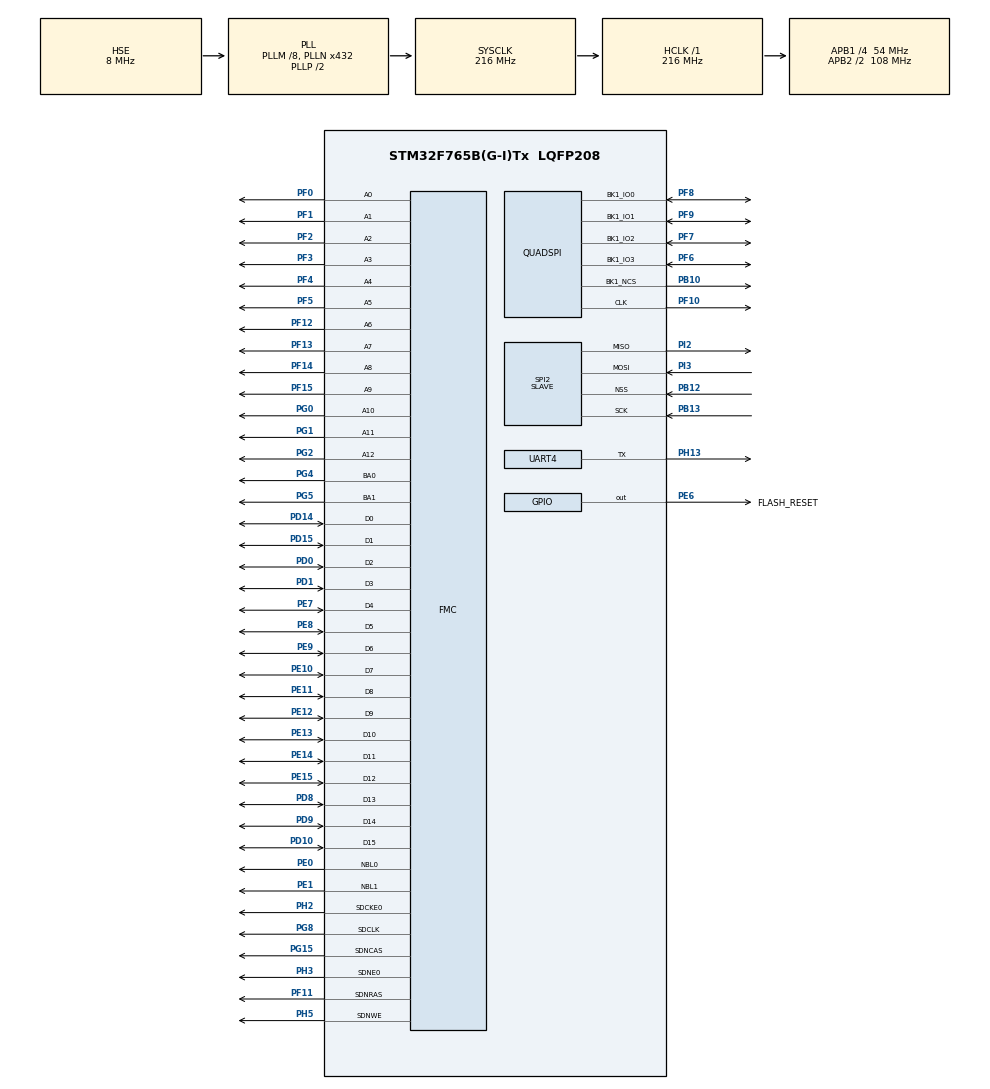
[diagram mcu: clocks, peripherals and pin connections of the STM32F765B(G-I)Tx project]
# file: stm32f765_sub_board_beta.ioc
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CORTEX_M7.ART_ACCLERATOR_ENABLE=1
CORTEX_M7.CPU_DCache=Enabled
CORTEX_M7.CPU_ICache=Enabled
CORTEX_M7.PREFETCH_ENABLE=1
FMC.CASLatency1=FMC_SDRAM_CAS_LATENCY_3
FMC.ColumnBitsNumber1=FMC_SDRAM_COLUMN_BITS_NUM_9
FMC.ExitSelfRefreshDelay1=8
FMC.LoadToActiveDelay1=2
FMC.RCDDelay1=2
FMC.RPDelay1=2
FMC.RPDelay2=2
FMC.ReadBurst1=FMC_SDRAM_RBURST_ENABLE
FMC.ReadBurst2=FMC_SDRAM_RBURST_ENABLE
FMC.ReadPipeDelay1=FMC_SDRAM_RPIPE_DELAY_1
FMC.ReadPipeDelay2=FMC_SDRAM_RPIPE_DELAY_1
FMC.RowCycleDelay1=6
FMC.RowCycleDelay2=6
FMC.SDClockPeriod1=FMC_SDRAM_CLOCK_PERIOD_2
FMC.SDClockPeriod2=FMC_SDRAM_CLOCK_PERIOD_2
FMC.SelfRefreshTime1=6
FMC.WriteProtection1=FMC_SDRAM_WRITE_PROTECTION_DISABLE
FMC.WriteRecoveryTime1=4
Mcu.Family=STM32F7
Mcu.Name=STM32F765B(G-I)Tx
Mcu.Package=LQFP208
NVIC.PriorityGroup=NVIC_PRIORITYGROUP_4
NVIC.SPI2_IRQn=true\:2\:0\:true\:true\:true\:1
NVIC.TIM8_TRG_COM_TIM14_IRQn=true\:14\:0\:true\:false\:true
NVIC.UART4_IRQn=true\:6\:0\:true\:true\:true\:2
PB10.Mode=Single Bank 1
PB10.Signal=QUADSPI_BK1_NCS
PB12.Mode=NSS_Signal_Hard_Input
PB12.Signal=SPI2_NSS
PB13.Mode=Full_Duplex_Slave
PB13.Signal=SPI2_SCK
PD0.Signal=FMC_D2_DA2
PD1.Signal=FMC_D3_DA3
PD10.Signal=FMC_D15_DA15
PD14.Signal=FMC_D0_DA0
PD15.Signal=FMC_D1_DA1
PD8.Signal=FMC_D13_DA13
PD9.Signal=FMC_D14_DA14
PE0.Signal=FMC_NBL0
PE1.Signal=FMC_NBL1
PE10.Signal=FMC_D7_DA7
PE11.Signal=FMC_D8_DA8
PE12.Signal=FMC_D9_DA9
PE13.Signal=FMC_D10_DA10
PE14.Signal=FMC_D11_DA11
PE15.Signal=FMC_D12_DA12
PE6.GPIO_Label=FLASH_RESET
PE6.PinState=GPIO_PIN_SET
PE6.Signal=GPIO_Output
PE7.Signal=FMC_D4_DA4
PE8.Signal=FMC_D5_DA5
PE9.Signal=FMC_D6_DA6
PF0.Signal=FMC_A0
PF1.Signal=FMC_A1
PF10.Mode=Single Bank 1
PF10.Signal=QUADSPI_CLK
PF11.Signal=FMC_SDNRAS
PF12.Signal=FMC_A6
PF13.Signal=FMC_A7
PF14.Signal=FMC_A8
PF15.Signal=FMC_A9
PF2.Signal=FMC_A2
PF3.Signal=FMC_A3
PF4.Signal=FMC_A4
PF5.Signal=FMC_A5
PF6.Mode=Single Bank 1
PF6.Signal=QUADSPI_BK1_IO3
PF7.Mode=Single Bank 1
PF7.Signal=QUADSPI_BK1_IO2
PF8.Mode=Single Bank 1
PF8.Signal=QUADSPI_BK1_IO0
PF9.Mode=Single Bank 1
PF9.Signal=QUADSPI_BK1_IO1
PG0.Signal=FMC_A10
PG1.Signal=FMC_A11
PG15.Signal=FMC_SDNCAS
PG2.Signal=FMC_A12
PG4.Signal=FMC_A14_BA0
PG5.Signal=FMC_A15_BA1
PG8.Signal=FMC_SDCLK
PH0/OSC_IN.Mode=HSE-External-Oscillator
PH0/OSC_IN.Signal=RCC_OSC_IN
PH1/OSC_OUT.Mode=HSE-External-Oscillator
PH1/OSC_OUT.Signal=RCC_OSC_OUT
PH13.Mode=Half_duplex(single_wire_mode)
PH13.Signal=UART4_TX
PH2.Mode=SdramChipSelect1_1
PH2.Signal=FMC_SDCKE0
PH3.Mode=SdramChipSelect1_1
PH3.Signal=FMC_SDNE0
PH5.Signal=FMC_SDNWE
PI2.Mode=Full_Duplex_Slave
PI2.Signal=SPI2_MISO
PI3.Mode=Full_Duplex_Slave
PI3.Signal=SPI2_MOSI
ProjectManager.HeapSize=0x400
ProjectManager.StackSize=0x800
ProjectManager.TargetToolchain=MDK-ARM V5
QUADSPI.ChipSelectHighTime=QSPI_CS_HIGH_TIME_4_CYCLE
QUADSPI.ClockPrescaler=2
QUADSPI.FifoThreshold=8
QUADSPI.FlashSize=26
QUADSPI.SampleShifting=QSPI_SAMPLE_SHIFTING_HALFCYCLE
RCC.AHBFreq_Value=216000000
RCC.APB1CLKDivider=RCC_HCLK_DIV4
RCC.APB1Freq_Value=54000000
RCC.APB1TimFreq_Value=108000000
RCC.APB2CLKDivider=RCC_HCLK_DIV2
RCC.APB2Freq_Value=108000000
RCC.APB2TimFreq_Value=216000000
RCC.CortexFreq_Value=216000000
RCC.EnbaleCSS=true
RCC.HCLKFreq_Value=216000000
RCC.HSE_VALUE=8000000
RCC.HSI_VALUE=16000000
RCC.LSE_VALUE=32768
RCC.PLLM=8
RCC.PLLN=432
RCC.PLLSourceVirtual=RCC_PLLSOURCE_HSE
RCC.SYSCLKFreq_VALUE=216000000
RCC.SYSCLKSource=RCC_SYSCLKSOURCE_PLLCLK
RCC.UART4CLockSelection=RCC_UART4CLKSOURCE_SYSCLK
RCC.USBFreq_Value=216000000
RCC.VCOOutputFreq_Value=432000000
SH.FMC_A0.0=FMC_A0,13b-sda1
SH.FMC_A1.0=FMC_A1,13b-sda1
SH.FMC_A10.0=FMC_A10,13b-sda1
SH.FMC_A11.0=FMC_A11,13b-sda1
SH.FMC_A12.0=FMC_A12,13b-sda1
SH.FMC_A14_BA0.0=FMC_BA0,FourSdramBanks1
SH.FMC_A15_BA1.0=FMC_BA1,FourSdramBanks1
SH.FMC_A2.0=FMC_A2,13b-sda1
SH.FMC_A3.0=FMC_A3,13b-sda1
SH.FMC_A4.0=FMC_A4,13b-sda1
SH.FMC_A5.0=FMC_A5,13b-sda1
SH.FMC_A6.0=FMC_A6,13b-sda1
SH.FMC_A7.0=FMC_A7,13b-sda1
SH.FMC_A8.0=FMC_A8,13b-sda1
SH.FMC_A9.0=FMC_A9,13b-sda1
SH.FMC_D0_DA0.0=FMC_D0,sd-16b-d1
SH.FMC_D10_DA10.0=FMC_D10,sd-16b-d1
SH.FMC_D11_DA11.0=FMC_D11,sd-16b-d1
SH.FMC_D12_DA12.0=FMC_D12,sd-16b-d1
SH.FMC_D13_DA13.0=FMC_D13,sd-16b-d1
SH.FMC_D14_DA14.0=FMC_D14,sd-16b-d1
SH.FMC_D15_DA15.0=FMC_D15,sd-16b-d1
SH.FMC_D1_DA1.0=FMC_D1,sd-16b-d1
SH.FMC_D2_DA2.0=FMC_D2,sd-16b-d1
SH.FMC_D3_DA3.0=FMC_D3,sd-16b-d1
SH.FMC_D4_DA4.0=FMC_D4,sd-16b-d1
SH.FMC_D5_DA5.0=FMC_D5,sd-16b-d1
SH.FMC_D6_DA6.0=FMC_D6,sd-16b-d1
SH.FMC_D7_DA7.0=FMC_D7,sd-16b-d1
SH.FMC_D8_DA8.0=FMC_D8,sd-16b-d1
SH.FMC_D9_DA9.0=FMC_D9,sd-16b-d1
SH.FMC_NBL0.0=FMC_NBL0,Sd2ByteEnable1
SH.FMC_NBL1.0=FMC_NBL1,Sd2ByteEnable1
SH.FMC_SDCLK.0=FMC_SDCLK,13b-sda1
SH.FMC_SDNCAS.0=FMC_SDNCAS,13b-sda1
SH.FMC_SDNRAS.0=FMC_SDNRAS,13b-sda1
SH.FMC_SDNWE.0=FMC_SDNWE,13b-sda1
SPI2.CLKPhase=SPI_PHASE_2EDGE
SPI2.CLKPolarity=SPI_POLARITY_HIGH
SPI2.DataSize=SPI_DATASIZE_8BIT
SPI2.Direction=SPI_DIRECTION_2LINES
SPI2.Mode=SPI_MODE_SLAVE
SPI2.VirtualNSS=VM_NSSHARD
SPI2.VirtualType=VM_SLAVE
TIM14.AutoReloadPreload=TIM_AUTORELOAD_PRELOAD_ENABLE
TIM14.ClockDivision=TIM_CLOCKDIVISION_DIV2
TIM14.Period=5000
TIM14.Prescaler=10799
UART4.BaudRate=460800
UART4.DMADisableonRxErrorParam=UART_ADVFEATURE_DMA_DISABLEONRXERROR
UART4.Mode=MODE_TX
UART4.WordLength=WORDLENGTH_8B
VP_TIM14_VS_ClockSourceINT.Mode=Enable_Timer
board=stm32f765_sub_board_beta

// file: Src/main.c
/**
  ******************************************************************************
  * File Name          : main.c
  * Description        : Main program body
  ******************************************************************************
  ** This notice applies to any and all portions of this file
  * that are not between comment pairs USER CODE BEGIN and
  * USER CODE END. Other portions of this file, whether
  * inserted by the user or by software development tools
  * are owned by their respective copyright owners.
  *
  * COPYRIGHT(c) 2017 STMicroelectronics
  *
  * Redistribution and use in source and binary forms, with or without modification,
  * are permitted provided that the following conditions are met:
  *   1. Redistributions of source code must retain the above copyright notice,
  *      this list of conditions and the following disclaimer.
  *   2. Redistributions in binary form must reproduce the above copyright notice,
  *      this list of conditions and the following disclaimer in the documentation
  *      and/or other materials provided with the distribution.
  *   3. Neither the name of STMicroelectronics nor the names of its contributors
  *      may be used to endorse or promote products derived from this software
  *      without specific prior written permission.
  *
  * THIS SOFTWARE IS PROVIDED BY THE COPYRIGHT HOLDERS AND CONTRIBUTORS "AS IS"
  * AND ANY EXPRESS OR IMPLIED WARRANTIES, INCLUDING, BUT NOT LIMITED TO, THE
  * IMPLIED WARRANTIES OF MERCHANTABILITY AND FITNESS FOR A PARTICULAR PURPOSE ARE
  * DISCLAIMED. IN NO EVENT SHALL THE COPYRIGHT HOLDER OR CONTRIBUTORS BE LIABLE
  * FOR ANY DIRECT, INDIRECT, INCIDENTAL, SPECIAL, EXEMPLARY, OR CONSEQUENTIAL
  * DAMAGES (INCLUDING, BUT NOT LIMITED TO, PROCUREMENT OF SUBSTITUTE GOODS OR
  * SERVICES; LOSS OF USE, DATA, OR PROFITS; OR BUSINESS INTERRUPTION) HOWEVER
  * CAUSED AND ON ANY THEORY OF LIABILITY, WHETHER IN CONTRACT, STRICT LIABILITY,
  * OR TORT (INCLUDING NEGLIGENCE OR OTHERWISE) ARISING IN ANY WAY OUT OF THE USE
  * OF THIS SOFTWARE, EVEN IF ADVISED OF THE POSSIBILITY OF SUCH DAMAGE.
  *
  ******************************************************************************
  */
#include "main.h"
#include "stm32f7xx_hal.h"
#include "quadspi.h"
#include "spi.h"
#include "tim.h"
#include "usart.h"
#include "gpio.h"
#include "fmc.h"

/* USER CODE BEGIN Includes */
#include "uart.h"
#include "sdram.h"
#include "bsp_qspi_n25q.h"
/* USER CODE END Includes */

/* USER CODE BEGIN PV */
/* Private variables ---------------------------------------------------------*/

/* USER CODE END PV */

void SystemClock_Config(void);
static void MX_NVIC_Init(void);

/* USER CODE BEGIN PFP */
/* Private function prototypes -----------------------------------------------*/

/* USER CODE END PFP */

int main(void)
{

  /* Enable I-Cache-------------------------------------------------------------*/
  SCB_EnableICache();

  /* Enable D-Cache-------------------------------------------------------------*/
  SCB_EnableDCache();

  /* MCU Configuration----------------------------------------------------------*/

  /* Reset of all peripherals, Initializes the Flash interface and the Systick. */
  HAL_Init();

  /* Configure the system clock */
  SystemClock_Config();

  /* Initialize all configured peripherals */
  MX_GPIO_Init();
  MX_SPI2_Init();
  MX_FMC_Init();
  MX_UART4_Init();
  MX_TIM14_Init();
  MX_QUADSPI_Init();

  /* Initialize interrupts */
  MX_NVIC_Init();

  /* Infinite loop */
  while (1)
  {

  }

}

/** System Clock Configuration
*/
void SystemClock_Config(void)
{

  RCC_OscInitTypeDef RCC_OscInitStruct;
  RCC_ClkInitTypeDef RCC_ClkInitStruct;
  RCC_PeriphCLKInitTypeDef PeriphClkInitStruct;

    /**Configure the main internal regulator output voltage
    */
  __HAL_RCC_PWR_CLK_ENABLE();

  __HAL_PWR_VOLTAGESCALING_CONFIG(PWR_REGULATOR_VOLTAGE_SCALE1);

    /**Initializes the CPU, AHB and APB busses clocks
    */
  RCC_OscInitStruct.OscillatorType = RCC_OSCILLATORTYPE_HSE;
  RCC_OscInitStruct.HSEState = RCC_HSE_ON;
  RCC_OscInitStruct.PLL.PLLState = RCC_PLL_ON;
  RCC_OscInitStruct.PLL.PLLSource = RCC_PLLSOURCE_HSE;
  RCC_OscInitStruct.PLL.PLLM = 8;
  RCC_OscInitStruct.PLL.PLLN = 432;
  RCC_OscInitStruct.PLL.PLLP = RCC_PLLP_DIV2;
  RCC_OscInitStruct.PLL.PLLQ = 2;
  if (HAL_RCC_OscConfig(&RCC_OscInitStruct) != HAL_OK)
  {
    _Error_Handler(__FILE__, __LINE__);
  }

    /**Activate the Over-Drive mode
    */
  if (HAL_PWREx_EnableOverDrive() != HAL_OK)
  {
    _Error_Handler(__FILE__, __LINE__);
  }

    /**Initializes the CPU, AHB and APB busses clocks
    */
  RCC_ClkInitStruct.ClockType = RCC_CLOCKTYPE_HCLK|RCC_CLOCKTYPE_SYSCLK
                              |RCC_CLOCKTYPE_PCLK1|RCC_CLOCKTYPE_PCLK2;
  RCC_ClkInitStruct.SYSCLKSource = RCC_SYSCLKSOURCE_PLLCLK;
  RCC_ClkInitStruct.AHBCLKDivider = RCC_SYSCLK_DIV1;
  RCC_ClkInitStruct.APB1CLKDivider = RCC_HCLK_DIV4;
  RCC_ClkInitStruct.APB2CLKDivider = RCC_HCLK_DIV2;

  if (HAL_RCC_ClockConfig(&RCC_ClkInitStruct, FLASH_LATENCY_7) != HAL_OK)
  {
    _Error_Handler(__FILE__, __LINE__);
  }

  PeriphClkInitStruct.PeriphClockSelection = RCC_PERIPHCLK_UART4;
  PeriphClkInitStruct.Uart4ClockSelection = RCC_UART4CLKSOURCE_SYSCLK;
  if (HAL_RCCEx_PeriphCLKConfig(&PeriphClkInitStruct) != HAL_OK)
  {
    _Error_Handler(__FILE__, __LINE__);
  }

    /**Enables the Clock Security System
    */
  HAL_RCC_EnableCSS();

    /**Configure the Systick interrupt time
    */
  HAL_SYSTICK_Config(HAL_RCC_GetHCLKFreq()/1000);

    /**Configure the Systick
    */
  HAL_SYSTICK_CLKSourceConfig(SYSTICK_CLKSOURCE_HCLK);

  /* SysTick_IRQn interrupt configuration */
  HAL_NVIC_SetPriority(SysTick_IRQn, 0, 0);
}

/** NVIC Configuration
*/
static void MX_NVIC_Init(void)
{
  /* SPI2_IRQn interrupt configuration */
  HAL_NVIC_SetPriority(SPI2_IRQn, 2, 0);
  HAL_NVIC_EnableIRQ(SPI2_IRQn);
  /* UART4_IRQn interrupt configuration */
  HAL_NVIC_SetPriority(UART4_IRQn, 6, 0);
  HAL_NVIC_EnableIRQ(UART4_IRQn);
}

void _Error_Handler(char * file, int line)
{
  while(1)
  {
  }
}

/************************ (C) COPYRIGHT STMicroelectronics *****END OF FILE****/
